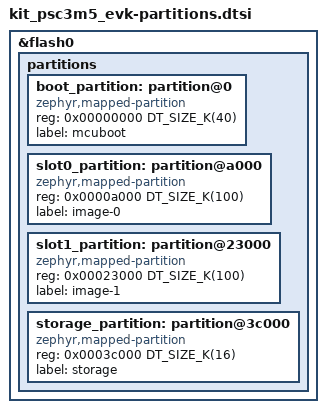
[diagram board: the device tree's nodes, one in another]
/*
 * SPDX-FileCopyrightText: Copyright (c) 2026 Infineon Technologies AG,
 * SPDX-FileCopyrightText: or an affiliate of Infineon Technologies AG. All rights reserved.
 *
 * SPDX-License-Identifier: Apache-2.0
 */

&flash0 {
	partitions {
		ranges;
		#address-cells = <1>;
		#size-cells = <1>;

		boot_partition: partition@0 {
			compatible = "zephyr,mapped-partition";
			reg = <0x00000000 DT_SIZE_K(40)>;
			label = "mcuboot";
		};

		slot0_partition: partition@a000 {
			compatible = "zephyr,mapped-partition";
			reg = <0x0000a000 DT_SIZE_K(100)>;
			label = "image-0";
		};

		slot1_partition: partition@23000 {
			compatible = "zephyr,mapped-partition";
			reg = <0x00023000 DT_SIZE_K(100)>;
			label = "image-1";
		};

		storage_partition: partition@3c000 {
			compatible = "zephyr,mapped-partition";
			reg = <0x0003c000 DT_SIZE_K(16)>;
			label = "storage";
		};
	};
};
